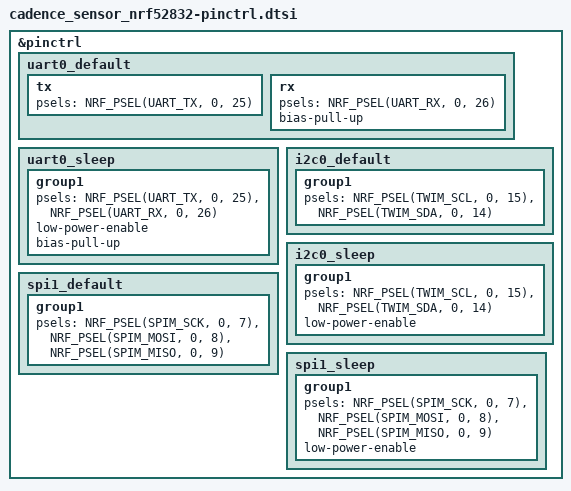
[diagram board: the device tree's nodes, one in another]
#include <zephyr/dt-bindings/pinctrl/nrf-pinctrl.h>

&pinctrl {
	uart0_default: uart0_default {
		tx {
			psels = <NRF_PSEL(UART_TX, 0, 25)>;
		};
		rx {
			psels = <NRF_PSEL(UART_RX, 0, 26)>;
			bias-pull-up;
		};
	};
	uart0_sleep: uart0_sleep {
		group1 {
			psels = <NRF_PSEL(UART_TX, 0, 25)>, <NRF_PSEL(UART_RX, 0, 26)>;
			low-power-enable;
			bias-pull-up;
		};
	};
	i2c0_default: i2c0_default {
		group1 {
			psels = <NRF_PSEL(TWIM_SCL, 0, 15)>,
				<NRF_PSEL(TWIM_SDA, 0, 14)>;
		};
	};
	i2c0_sleep: i2c0_sleep {
		group1 {
			psels = <NRF_PSEL(TWIM_SCL, 0, 15)>,
				<NRF_PSEL(TWIM_SDA, 0, 14)>;
			low-power-enable;
		};
	};
	spi1_default: spi1_default {
		group1 {
			psels = <NRF_PSEL(SPIM_SCK, 0, 7)>,
				<NRF_PSEL(SPIM_MOSI, 0, 8)>,
				<NRF_PSEL(SPIM_MISO, 0, 9)>;
		};
	};
	spi1_sleep: spi1_sleep {
		group1 {
			psels = <NRF_PSEL(SPIM_SCK, 0, 7)>,
				<NRF_PSEL(SPIM_MOSI, 0, 8)>,
				<NRF_PSEL(SPIM_MISO, 0, 9)>;
			low-power-enable;
		};
	};
};
